AUTOSAR XML (schema 00046)
package /DoorSensorAbstractionSWC_package
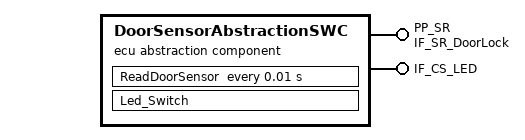
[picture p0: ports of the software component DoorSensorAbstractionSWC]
  ecu abstraction sw component type DoorSensorAbstractionSWC
    provide port PP_SR: provided-com-specs=nonqueued-sender-com-spec={data-element=DoorState, init-value=DoorState:0}, provided-interface=IF_SR_DoorLock
    provide port IF_CS_LED: server-com-spec=Led_Switch, provided-interface=IF_CS_LED
    behavior DoorSensorAbstractionSWC_internal_behavior
      timing event TE_10ms_event: start-on-event=ReadDoorSensor, period=0.01
      operation invoked event OIE_LedSwitch_event: start-on-event=Led_Switch, operation=IF_CS_LED.Led_Switch
      runnable ReadDoorSensor: symbol=ReadDoorSensor_runnable
        data-write-access:
          access ReadDoorSensor_PP_SR_DoorState: accessed-variable=PP_SR.DoorState
      runnable Led_Switch: symbol=Led_Switch_runnable
